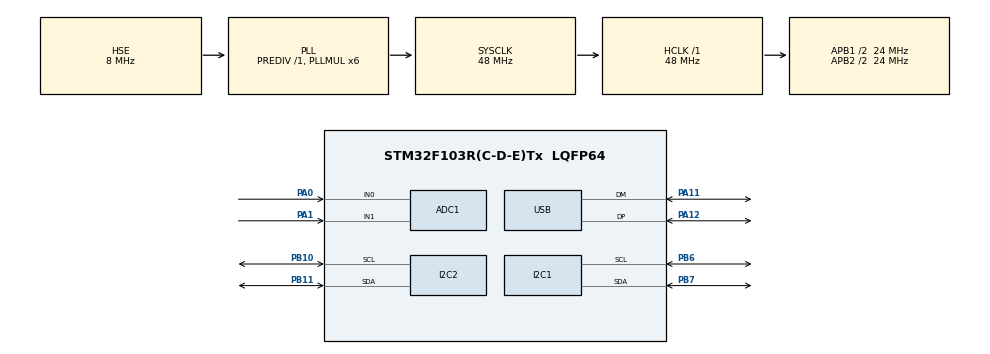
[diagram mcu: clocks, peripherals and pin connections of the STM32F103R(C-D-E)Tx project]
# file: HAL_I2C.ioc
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ADC1.Channel-0\#ChannelRegularConversion=ADC_CHANNEL_0
ADC1.NbrOfConversionFlag=1
ADC1.Rank-0\#ChannelRegularConversion=1
ADC1.SamplingTime-0\#ChannelRegularConversion=ADC_SAMPLETIME_1CYCLE_5
ADC1.master=1
Dma.I2C1_RX.0.Direction=DMA_PERIPH_TO_MEMORY
Dma.I2C1_RX.0.Instance=DMA1_Channel7
Dma.I2C1_RX.0.MemDataAlignment=DMA_MDATAALIGN_BYTE
Dma.I2C1_RX.0.MemInc=DMA_MINC_ENABLE
Dma.I2C1_RX.0.Mode=DMA_CIRCULAR
Dma.I2C1_RX.0.PeriphDataAlignment=DMA_PDATAALIGN_BYTE
Dma.I2C1_RX.0.PeriphInc=DMA_PINC_DISABLE
Dma.I2C1_RX.0.Priority=DMA_PRIORITY_LOW
Dma.I2C1_TX.1.Direction=DMA_MEMORY_TO_PERIPH
Dma.I2C1_TX.1.Instance=DMA1_Channel6
Dma.I2C1_TX.1.MemDataAlignment=DMA_MDATAALIGN_BYTE
Dma.I2C1_TX.1.MemInc=DMA_MINC_ENABLE
Dma.I2C1_TX.1.Mode=DMA_CIRCULAR
Dma.I2C1_TX.1.PeriphDataAlignment=DMA_PDATAALIGN_BYTE
Dma.I2C1_TX.1.PeriphInc=DMA_PINC_DISABLE
Dma.I2C1_TX.1.Priority=DMA_PRIORITY_LOW
Dma.Request0=I2C1_RX
Dma.Request1=I2C1_TX
Mcu.Family=STM32F1
Mcu.Name=STM32F103R(C-D-E)Tx
Mcu.Package=LQFP64
NVIC.DMA1_Channel6_IRQn=true\:0\:0\:false\:false\:true\:false
NVIC.DMA1_Channel7_IRQn=true\:0\:0\:false\:false\:true\:false
NVIC.I2C1_ER_IRQn=true\:0\:0\:false\:false\:true\:true
NVIC.I2C1_EV_IRQn=true\:0\:0\:false\:false\:true\:true
NVIC.PriorityGroup=NVIC_PRIORITYGROUP_4
NVIC.TIM4_IRQn=true\:0\:0\:false\:false\:true\:true
NVIC.USB_LP_CAN1_RX0_IRQn=true\:0\:0\:false\:false\:true\:false
PA0-WKUP.Signal=ADCx_IN0
PA1.Signal=ADCx_IN1
PA11.Mode=Device
PA11.Signal=USB_DM
PA12.Mode=Device
PA12.Signal=USB_DP
PB10.Mode=I2C
PB10.Signal=I2C2_SCL
PB11.Mode=I2C
PB11.Signal=I2C2_SDA
PB6.Mode=I2C
PB6.Signal=I2C1_SCL
PB7.Mode=I2C
PB7.Signal=I2C1_SDA
PD0-OSC_IN.Mode=HSE-External-Oscillator
PD0-OSC_IN.Signal=RCC_OSC_IN
PD1-OSC_OUT.Mode=HSE-External-Oscillator
PD1-OSC_OUT.Signal=RCC_OSC_OUT
ProjectManager.HeapSize=0x200
ProjectManager.StackSize=0x400
ProjectManager.TargetToolchain=EWARM
RCC.AHBFreq_Value=48000000
RCC.APB1CLKDivider=RCC_HCLK_DIV2
RCC.APB1Freq_Value=24000000
RCC.APB1TimFreq_Value=48000000
RCC.APB2CLKDivider=RCC_HCLK_DIV2
RCC.APB2Freq_Value=24000000
RCC.APB2TimCLKDivider=2
RCC.APB2TimFreq_Value=48000000
RCC.HCLKFreq_Value=48000000
RCC.PLLMUL=RCC_PLL_MUL6
RCC.SYSCLKFreq_VALUE=48000000
RCC.SYSCLKSource=RCC_SYSCLKSOURCE_PLLCLK
RCC.USBFreq_Value=48000000
SH.ADCx_IN0.0=ADC1_IN0,IN0
SH.ADCx_IN1.0=ADC1_IN1,IN1
TIM4.AutoReloadPreload=TIM_AUTORELOAD_PRELOAD_ENABLE
TIM4.Period=1000-1
TIM4.Prescaler=48-1
USB_DEVICE.CLASS_NAME_FS=CDC
USB_DEVICE.VirtualMode=Cdc
USB_DEVICE.VirtualModeFS=Cdc_FS
VP_SYS_VS_ND.Mode=No_Debug
VP_TIM4_VS_ClockSourceINT.Mode=Internal
VP_USB_DEVICE_VS_USB_DEVICE_CDC_FS.Mode=CDC_FS
board=HAL_I2C

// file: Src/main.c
/**
  ******************************************************************************
  * File Name          : main.c
  * Description        : Main program body
  ******************************************************************************
  * This notice applies to any and all portions of this file
  * that are not between comment pairs USER CODE BEGIN and
  * USER CODE END. Other portions of this file, whether
  * inserted by the user or by software development tools
  * are owned by their respective copyright owners.
  *
  * Copyright (c) 2017 STMicroelectronics International N.V.
  * All rights reserved.
  *
  * Redistribution and use in source and binary forms, with or without
  * modification, are permitted, provided that the following conditions are met:
  *
  * 1. Redistribution of source code must retain the above copyright notice,
  *    this list of conditions and the following disclaimer.
  * 2. Redistributions in binary form must reproduce the above copyright notice,
  *    this list of conditions and the following disclaimer in the documentation
  *    and/or other materials provided with the distribution.
  * 3. Neither the name of STMicroelectronics nor the names of other
  *    contributors to this software may be used to endorse or promote products
  *    derived from this software without specific written permission.
  * 4. This software, including modifications and/or derivative works of this
  *    software, must execute solely and exclusively on microcontroller or
  *    microprocessor devices manufactured by or for STMicroelectronics.
  * 5. Redistribution and use of this software other than as permitted under
  *    this license is void and will automatically terminate your rights under
  *    this license.
  *
  * THIS SOFTWARE IS PROVIDED BY STMICROELECTRONICS AND CONTRIBUTORS "AS IS"
  * AND ANY EXPRESS, IMPLIED OR STATUTORY WARRANTIES, INCLUDING, BUT NOT
  * LIMITED TO, THE IMPLIED WARRANTIES OF MERCHANTABILITY, FITNESS FOR A
  * PARTICULAR PURPOSE AND NON-INFRINGEMENT OF THIRD PARTY INTELLECTUAL PROPERTY
  * RIGHTS ARE DISCLAIMED TO THE FULLEST EXTENT PERMITTED BY LAW. IN NO EVENT
  * SHALL STMICROELECTRONICS OR CONTRIBUTORS BE LIABLE FOR ANY DIRECT, INDIRECT,
  * INCIDENTAL, SPECIAL, EXEMPLARY, OR CONSEQUENTIAL DAMAGES (INCLUDING, BUT NOT
  * LIMITED TO, PROCUREMENT OF SUBSTITUTE GOODS OR SERVICES; LOSS OF USE, DATA,
  * OR PROFITS; OR BUSINESS INTERRUPTION) HOWEVER CAUSED AND ON ANY THEORY OF
  * LIABILITY, WHETHER IN CONTRACT, STRICT LIABILITY, OR TORT (INCLUDING
  * NEGLIGENCE OR OTHERWISE) ARISING IN ANY WAY OUT OF THE USE OF THIS SOFTWARE,
  * EVEN IF ADVISED OF THE POSSIBILITY OF SUCH DAMAGE.
  *
  ******************************************************************************
  */

#include "main.h"
#include "stm32f1xx_hal.h"
#include "adc.h"
#include "dma.h"
#include "i2c.h"
#include "tim.h"
#include "usb_device.h"
#include "gpio.h"

/* USER CODE BEGIN PV */
/* Private variables ---------------------------------------------------------*/
#define ADDR_DEV_Write  0x90
#define ADDR_DEV_Read   0x91
uint8_t i2cBuff[10] = {0xAA};

/* USER CODE END PV */

void SystemClock_Config(void);

/* USER CODE BEGIN PFP */
/* Private function prototypes -----------------------------------------------*/

/* USER CODE END PFP */

int main(void)
{

  /* MCU Configuration----------------------------------------------------------*/

  /* Reset of all peripherals, Initializes the Flash interface and the Systick. */
  HAL_Init();

  /* Configure the system clock */
  SystemClock_Config();

  /* Initialize all configured peripherals */
  MX_GPIO_Init();
  MX_DMA_Init();
  MX_USB_DEVICE_Init();
  MX_I2C1_Init();
  MX_TIM4_Init();
  MX_I2C2_Init();
  MX_ADC1_Init();

  /* Infinite loop */
  while (1)
  {

  /* USER CODE BEGIN 3 */
    HAL_I2C_Master_Transmit(&hi2c1,ADDR_DEV_Write,i2cBuff,10,0xFFFF);
    HAL_Delay(100);

  }
  /* USER CODE END 3 */

}

/** System Clock Configuration
*/
void SystemClock_Config(void)
{

  RCC_OscInitTypeDef RCC_OscInitStruct;
  RCC_ClkInitTypeDef RCC_ClkInitStruct;
  RCC_PeriphCLKInitTypeDef PeriphClkInit;

    /**Initializes the CPU, AHB and APB busses clocks
    */
  RCC_OscInitStruct.OscillatorType = RCC_OSCILLATORTYPE_HSE;
  RCC_OscInitStruct.HSEState = RCC_HSE_ON;
  RCC_OscInitStruct.HSEPredivValue = RCC_HSE_PREDIV_DIV1;
  RCC_OscInitStruct.HSIState = RCC_HSI_ON;
  RCC_OscInitStruct.PLL.PLLState = RCC_PLL_ON;
  RCC_OscInitStruct.PLL.PLLSource = RCC_PLLSOURCE_HSE;
  RCC_OscInitStruct.PLL.PLLMUL = RCC_PLL_MUL6;
  if (HAL_RCC_OscConfig(&RCC_OscInitStruct) != HAL_OK)
  {
    _Error_Handler(__FILE__, __LINE__);
  }

    /**Initializes the CPU, AHB and APB busses clocks
    */
  RCC_ClkInitStruct.ClockType = RCC_CLOCKTYPE_HCLK|RCC_CLOCKTYPE_SYSCLK
                              |RCC_CLOCKTYPE_PCLK1|RCC_CLOCKTYPE_PCLK2;
  RCC_ClkInitStruct.SYSCLKSource = RCC_SYSCLKSOURCE_PLLCLK;
  RCC_ClkInitStruct.AHBCLKDivider = RCC_SYSCLK_DIV1;
  RCC_ClkInitStruct.APB1CLKDivider = RCC_HCLK_DIV2;
  RCC_ClkInitStruct.APB2CLKDivider = RCC_HCLK_DIV2;

  if (HAL_RCC_ClockConfig(&RCC_ClkInitStruct, FLASH_LATENCY_1) != HAL_OK)
  {
    _Error_Handler(__FILE__, __LINE__);
  }

  PeriphClkInit.PeriphClockSelection = RCC_PERIPHCLK_ADC|RCC_PERIPHCLK_USB;
  PeriphClkInit.AdcClockSelection = RCC_ADCPCLK2_DIV2;
  PeriphClkInit.UsbClockSelection = RCC_USBCLKSOURCE_PLL;
  if (HAL_RCCEx_PeriphCLKConfig(&PeriphClkInit) != HAL_OK)
  {
    _Error_Handler(__FILE__, __LINE__);
  }

    /**Configure the Systick interrupt time
    */
  HAL_SYSTICK_Config(HAL_RCC_GetHCLKFreq()/1000);

    /**Configure the Systick
    */
  HAL_SYSTICK_CLKSourceConfig(SYSTICK_CLKSOURCE_HCLK);

  /* SysTick_IRQn interrupt configuration */
  HAL_NVIC_SetPriority(SysTick_IRQn, 0, 0);
}

void _Error_Handler(char * file, int line)
{
  while(1)
  {
  }
}

/************************ (C) COPYRIGHT STMicroelectronics *****END OF FILE****/
